# STM32U5xx register map
File version: 1.3
Registers are 32-bit, read-write, reset 0x0 unless marked. A register's access mark holds for its fields unless they carry their own. Offsets are from the block's base; [hi:lo] are bit positions; {n}, {i} and the like mark numbered series.

## RCC — Reset and clock control
Base 0x46020C00
Same registers: SEC_RCC 0x56020C00
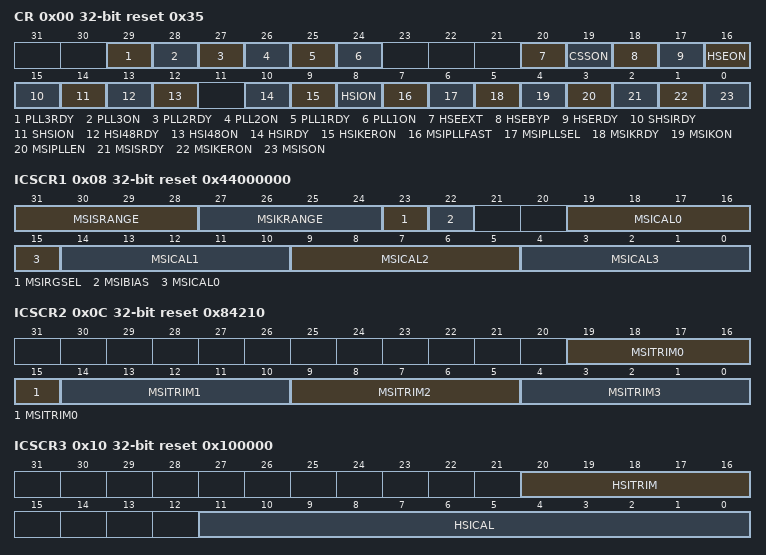
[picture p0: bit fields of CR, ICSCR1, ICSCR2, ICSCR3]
0x00 CR access per field reset 0x35 — Clock control register
  [29] PLL3RDY ro — PLL3 clock ready flag
  [28] PLL3ON rw — PLL3 enable
  [27] PLL2RDY ro — PLL2 clock ready flag
  [26] PLL2ON rw — PLL2 enable
  [25] PLL1RDY ro — PLL1 clock ready flag
  [24] PLL1ON rw — PLL1 enable
  [20] HSEEXT rw — SRAM3 page 5 (64 Kbytes) power-down in Stop modes
  [19] CSSON rw — Clock security system enable
  [18] HSEBYP rw — HSE crystal oscillator bypass
  [17] HSERDY ro — HSE clock ready flag
  [16] HSEON rw — HSE clock enable
  [15] SHSIRDY ro — SHSI clock ready flag
  [14] SHSION rw — SHSI clock enable
  [13] HSI48RDY ro — HSI48 clock ready flag
  [12] HSI48ON rw — HSI48 clock enable
  [10] HSIRDY ro — HSI16 clock ready flag
  [9] HSIKERON rw — HSI16 enable for some peripheral kernels
  [8] HSION rw — HSI16 clock enable
  [7] MSIPLLFAST rw — MSI PLL mode fast startup
  [6] MSIPLLSEL rw — MSI clock with PLL mode selection
  [5] MSIKRDY ro — MSIK clock ready flag
  [4] MSIKON rw — MSIK clock enable
  [3] MSIPLLEN rw — MSI clock PLL-mode enable
  [2] MSISRDY ro — MSIS clock ready flag
  [1] MSIKERON rw — MSI enable for some peripheral kernels
  [0] MSISON rw — MSIS clock enable
0x08 ICSCR1 access per field reset 0x44000000 — Internal clock sources calibration register 1
  [31:28] MSISRANGE rw — MSIS clock ranges
  [27:24] MSIKRANGE rw — MSIK clock ranges
  [23] MSIRGSEL rw — MSI clock range selection
  [22] MSIBIAS rw — MSI bias mode selection
  [19:15] MSICAL0 ro — MSI clock calibration
  [14:10] MSICAL1 ro — MSIRC1 clock calibration
  [9:5] MSICAL2 ro — MSIRC2 clock calibration
  [4:0] MSICAL3 ro — MSIRC3 clock calibration
0x0C ICSCR2 reset 0x84210 — Internal clock sources calibration register 2
  [19:15] MSITRIM0 — MSI clock calibration
  [14:10] MSITRIM1 — MSIRC1 clock calibration
  [9:5] MSITRIM2 — MSIRC2 clock calibration
  [4:0] MSITRIM3 — MSIRC3 clock calibration
0x10 ICSCR3 access per field reset 0x100000 — Internal clock sources calibration register 3
  [20:16] HSITRIM rw — HSI clock trimming
  [11:0] HSICAL ro — HSI clock calibration
0x14 CRRCR ro — clock recovery RC register
  [8:0] HSI48CAL — HSI48 clock calibration
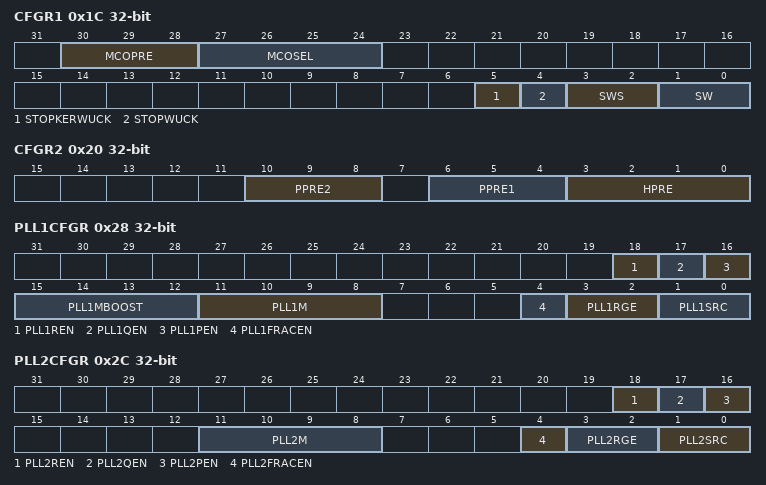
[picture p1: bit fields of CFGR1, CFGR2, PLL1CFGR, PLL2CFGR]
0x1C CFGR1 access per field — clock configuration register 1
  [30:28] MCOPRE rw — microcontroller clock output prescaler
  [27:24] MCOSEL rw — microcontroller clock output
  [5] STOPKERWUCK rw — wakeup from Stop kernel clock automatic enable selection
  [4] STOPWUCK rw — wakeup from Stop and CSS backup clock selection
  [3:2] SWS ro — system clock switch status
  [1:0] SW rw — system clock switch
0x20 CFGR2 — clock configuration register 2
  [10:8] PPRE2 — APB2 prescaler
  [6:4] PPRE1 — APB1 prescaler
  [3:0] HPRE — AHB prescaler
0x24 CFGR3 — clock configuration register 3
  [6:4] PPRE3 — APB3 prescaler
0x28 PLL1CFGR — PLL1 configuration register
  [18] PLL1REN — PLL1 DIVR divider output enable
  [17] PLL1QEN — PLL1 DIVQ divider output enable
  [16] PLL1PEN — PLL1 DIVP divider output enable
  [15:12] PLL1MBOOST — Prescaler for EPOD booster input clock
  [11:8] PLL1M — Prescaler for PLL1
  [4] PLL1FRACEN — PLL1 fractional latch enable
  [3:2] PLL1RGE — PLL1 input frequency range
  [1:0] PLL1SRC — PLL1 entry clock source
0x2C PLL2CFGR — PLL2 configuration register
  [18] PLL2REN — PLL2 DIVR divider output enable
  [17] PLL2QEN — PLL2 DIVQ divider output enable
  [16] PLL2PEN — PLL2 DIVP divider output enable
  [11:8] PLL2M — Prescaler for PLL2
  [4] PLL2FRACEN — PLL2 fractional latch enable
  [3:2] PLL2RGE — PLL2 input frequency range
  [1:0] PLL2SRC — PLL2 entry clock source
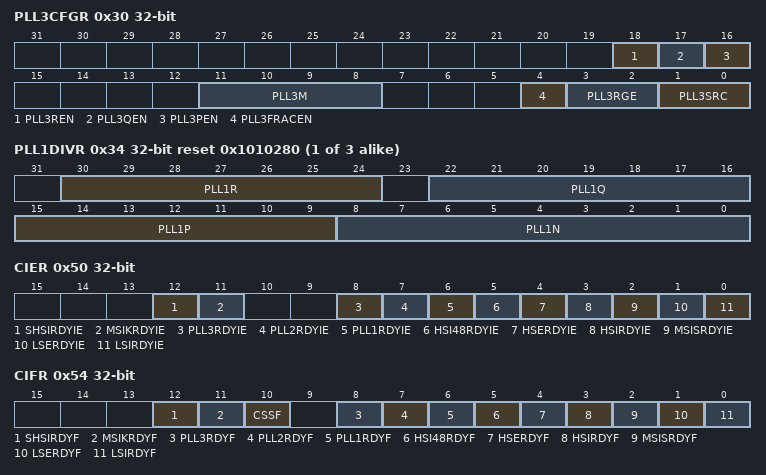
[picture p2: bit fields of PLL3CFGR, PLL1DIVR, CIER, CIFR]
0x30 PLL3CFGR — PLL3 configuration register
  [18] PLL3REN — PLL3 DIVR divider output enable
  [17] PLL3QEN — PLL3 DIVQ divider output enable
  [16] PLL3PEN — PLL3 DIVP divider output enable
  [11:8] PLL3M — Prescaler for PLL3
  [4] PLL3FRACEN — PLL3 fractional latch enable
  [3:2] PLL3RGE — PLL3 input frequency range
  [1:0] PLL3SRC — PLL3 entry clock source
{0x2C+8i} PLL{i}DIVR reset 0x1010280 (i=1..3) — PLL{i} dividers register
  [30:24] PLL{i}R — PLL{i} DIVR division factor
  [22:16] PLL{i}Q — PLL{i} DIVQ division factor
  [15:9] PLL{i}P — PLL{i} DIVP division factor
  [8:0] PLL{i}N — Multiplication factor for PLL{i} VCO
{0x30+8i} PLL{i}FRACR (i=1..3) — PLL{i} fractional divider register
  [15:3] PLL{i}FRACN — Fractional part of the multiplication factor for PLL{i} VCO
0x50 CIER — clock interrupt enable register
  [12] SHSIRDYIE — SHSI ready interrupt enable
  [11] MSIKRDYIE — MSIK ready interrupt enable
  [8] PLL3RDYIE — PLL3 ready interrupt enable
  [7] PLL2RDYIE — PLL2 ready interrupt enable
  [6] PLL1RDYIE — PLL ready interrupt enable
  [5] HSI48RDYIE — HSI48 ready interrupt enable
  [4] HSERDYIE — HSE ready interrupt enable
  [3] HSIRDYIE — HSI16 ready interrupt enable
  [2] MSISRDYIE — MSIS ready interrupt enable
  [1] LSERDYIE — LSE ready interrupt enable
  [0] LSIRDYIE — LSI ready interrupt enable
0x54 CIFR ro — clock interrupt flag register
  [12] SHSIRDYF — SHSI ready interrupt flag
  [11] MSIKRDYF — MSIK ready interrupt flag
  [10] CSSF — Clock security system interrupt flag
  [8] PLL3RDYF — PLL3 ready interrupt flag
  [7] PLL2RDYF — PLL2 ready interrupt flag
  [6] PLL1RDYF — PLL1 ready interrupt flag
  [5] HSI48RDYF — HSI48 ready interrupt flag
  [4] HSERDYF — HSE ready interrupt flag
  [3] HSIRDYF — HSI16 ready interrupt flag
  [2] MSISRDYF — MSIS ready interrupt flag
  [1] LSERDYF — LSE ready interrupt flag
  [0] LSIRDYF — LSI ready interrupt flag
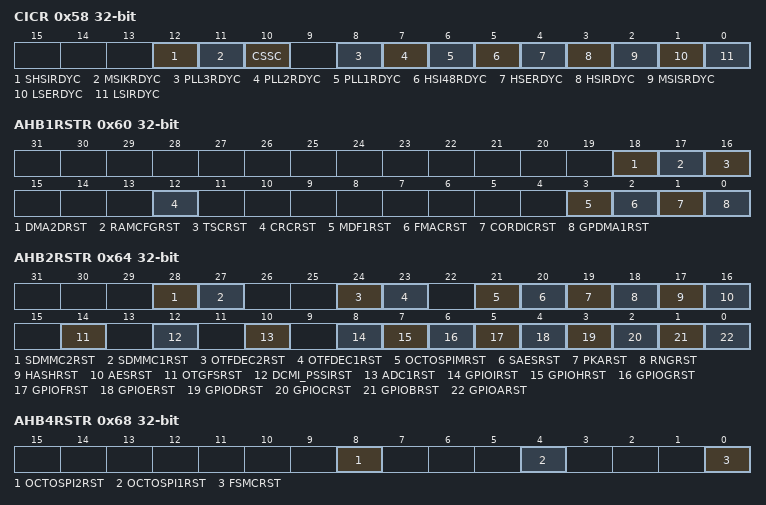
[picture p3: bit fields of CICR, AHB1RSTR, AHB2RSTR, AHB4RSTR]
0x58 CICR wo — clock interrupt clear register
  [12] SHSIRDYC — SHSI ready interrupt clear
  [11] MSIKRDYC — MSIK ready interrupt clear
  [10] CSSC — Clock security system interrupt clear
  [8] PLL3RDYC — PLL3 ready interrupt clear
  [7] PLL2RDYC — PLL2 ready interrupt clear
  [6] PLL1RDYC — PLL1 ready interrupt clear
  [5] HSI48RDYC — HSI48 ready interrupt clear
  [4] HSERDYC — HSE ready interrupt clear
  [3] HSIRDYC — HSI16 ready interrupt clear
  [2] MSISRDYC — MSIS ready interrupt clear
  [1] LSERDYC — LSE ready interrupt clear
  [0] LSIRDYC — LSI ready interrupt clear
0x60 AHB1RSTR — AHB1 peripheral reset register
  [18] DMA2DRST — DMA2D reset
  [17] RAMCFGRST — RAMCFG reset
  [16] TSCRST — TSC reset
  [12] CRCRST — CRC reset
  [3] MDF1RST — MDF1 reset
  [2] FMACRST — FMAC reset
  [1] CORDICRST — CORDIC reset
  [0] GPDMA1RST — GPDMA1 reset
0x64 AHB2RSTR — AHB2 peripheral reset register
  [28] SDMMC2RST — SDMMC2 reset
  [27] SDMMC1RST — SDMMC1 reset
  [24] OTFDEC2RST — OTFDEC2 reset
  [23] OTFDEC1RST — OTFDEC1 reset
  [21] OCTOSPIMRST — OCTOSPIM reset
  [20] SAESRST — SAES hardware accelerator reset
  [19] PKARST — PKA reset
  [18] RNGRST — Random number generator reset
  [17] HASHRST — Hash reset
  [16] AESRST — AES hardware accelerator reset
  [14] OTGFSRST — OTGFS reset
  [12] DCMI_PSSIRST — DCMI and PSSI reset
  [10] ADC1RST — ADC1 reset
  [8] GPIOIRST — O port I reset
  [7] GPIOHRST — O port H reset
  [6] GPIOGRST — O port G reset
  [5] GPIOFRST — O port F reset
  [4] GPIOERST — O port E reset
  [3] GPIODRST — O port D reset
  [2] GPIOCRST — O port C reset
  [1] GPIOBRST — O port B reset
  [0] GPIOARST — O port A reset
0x68 AHB4RSTR — AHB4 peripheral reset register
  [8] OCTOSPI2RST — OCTOSPI2 reset
  [4] OCTOSPI1RST — OCTOSPI1 reset
  [0] FSMCRST — Flexible memory controller reset
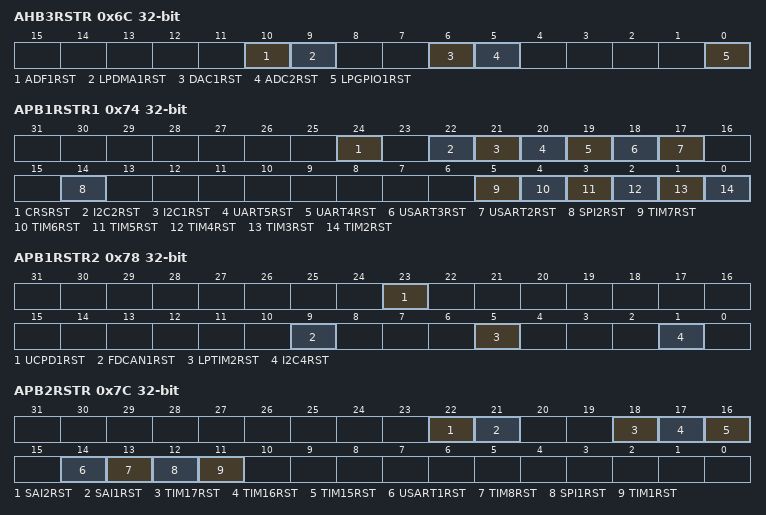
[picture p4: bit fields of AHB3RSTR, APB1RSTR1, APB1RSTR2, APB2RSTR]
0x6C AHB3RSTR — AHB3 peripheral reset register
  [10] ADF1RST — ADF1 reset
  [9] LPDMA1RST — LPDMA1 reset
  [6] DAC1RST — DAC1 reset
  [5] ADC2RST — ADC2 reset
  [0] LPGPIO1RST — LPGPIO1 reset
0x74 APB1RSTR1 — APB1 peripheral reset register 1
  [24] CRSRST — CRS reset
  [22] I2C2RST — I2C2 reset
  [21] I2C1RST — I2C1 reset
  [20] UART5RST — UART5 reset
  [19] UART4RST — UART4 reset
  [18] USART3RST — USART3 reset
  [17] USART2RST — USART2 reset
  [14] SPI2RST — SPI2 reset
  [5] TIM7RST — TIM7 reset
  [4] TIM6RST — TIM6 reset
  [3] TIM5RST — TIM5 reset
  [2] TIM4RST — TIM3 reset
  [1] TIM3RST — TIM3 reset
  [0] TIM2RST — TIM2 reset
0x78 APB1RSTR2 — APB1 peripheral reset register 2
  [23] UCPD1RST — UCPD1 reset
  [9] FDCAN1RST — FDCAN1 reset
  [5] LPTIM2RST — LPTIM2 reset
  [1] I2C4RST — I2C4 Reset
0x7C APB2RSTR — APB2 peripheral reset register
  [22] SAI2RST — SAI2 reset
  [21] SAI1RST — SAI1 reset
  [18] TIM17RST — TIM17 reset
  [17] TIM16RST — TIM16 reset
  [16] TIM15RST — TIM15 reset
  [14] USART1RST — USART1 reset
  [13] TIM8RST — TIM8 reset
  [12] SPI1RST — SPI1 reset
  [11] TIM1RST — TIM1 reset
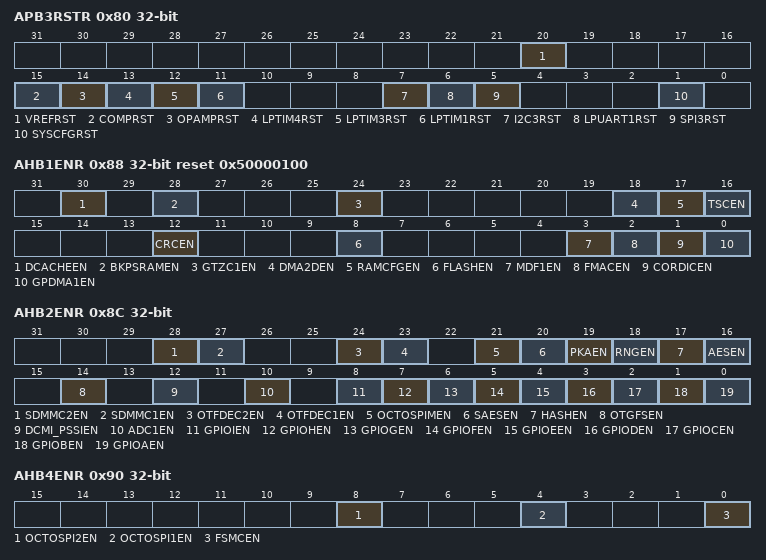
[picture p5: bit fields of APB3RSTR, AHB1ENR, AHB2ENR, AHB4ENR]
0x80 APB3RSTR — APB3 peripheral reset register
  [20] VREFRST — VREFBUF reset
  [15] COMPRST — COMP reset
  [14] OPAMPRST — OPAMP reset
  [13] LPTIM4RST — LPTIM4 reset
  [12] LPTIM3RST — LPTIM3 reset
  [11] LPTIM1RST — LPTIM1 reset
  [7] I2C3RST — I2C3 reset
  [6] LPUART1RST — LPUART1 reset
  [5] SPI3RST — SPI3 reset
  [1] SYSCFGRST — SYSCFG reset
0x88 AHB1ENR reset 0x50000100 — AHB1 peripheral clock enable register
  [30] DCACHEEN — DCACHE clock enable
  [28] BKPSRAMEN — BKPSRAM clock enable
  [24] GTZC1EN — GTZC1 clock enable
  [18] DMA2DEN — DMA2D clock enable
  [17] RAMCFGEN — RAMCFG clock enable
  [16] TSCEN — Touch sensing controller clock enable
  [12] CRCEN — CRC clock enable
  [8] FLASHEN — FLASH clock enable
  [3] MDF1EN — MDF1 clock enable
  [2] FMACEN — FMAC clock enable
  [1] CORDICEN — CORDIC clock enable
  [0] GPDMA1EN — GPDMA1 clock enable
0x8C AHB2ENR — AHB2 peripheral clock enable register
  [28] SDMMC2EN — SDMMC2 clock enable
  [27] SDMMC1EN — SDMMC1 clock enable
  [24] OTFDEC2EN — OTFDEC2 clock enable
  [23] OTFDEC1EN — OTFDEC1 clock enable
  [21] OCTOSPIMEN — OCTOSPIM clock enable
  [20] SAESEN — SAES clock enable
  [19] PKAEN — PKA clock enable
  [18] RNGEN — RNG clock enable
  [17] HASHEN — HASH clock enable
  [16] AESEN — AES clock enable
  [14] OTGFSEN — OTGFS clock enable
  [12] DCMI_PSSIEN — DCMI and PSSI clock enable
  [10] ADC1EN — ADC1 clock enable
  [8] GPIOIEN — IO port I clock enable
  [7] GPIOHEN — IO port H clock enable
  [6] GPIOGEN — IO port G clock enable
  [5] GPIOFEN — IO port F clock enable
  [4] GPIOEEN — IO port E clock enable
  [3] GPIODEN — IO port D clock enable
  [2] GPIOCEN — IO port C clock enable
  [1] GPIOBEN — IO port B clock enable
  [0] GPIOAEN — IO port A clock enable
0x90 AHB4ENR — AHB4 peripheral clock enable register
  [8] OCTOSPI2EN — OCTOSPI2 clock enable
  [4] OCTOSPI1EN — OCTOSPI1 clock enable
  [0] FSMCEN — FSMC clock enable
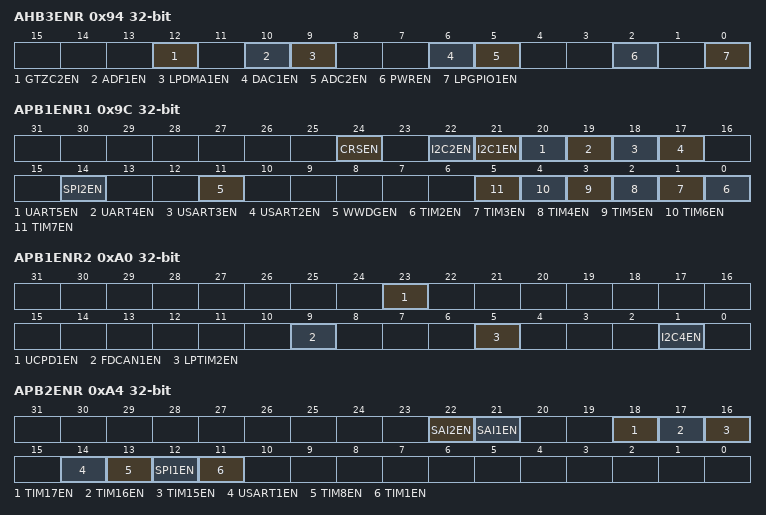
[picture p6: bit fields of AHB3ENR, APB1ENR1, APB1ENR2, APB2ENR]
0x94 AHB3ENR — AHB3 peripheral clock enable register
  [12] GTZC2EN — GTZC2 clock enable
  [10] ADF1EN — ADF1 clock enable
  [9] LPDMA1EN — LPDMA1 clock enable
  [6] DAC1EN — DAC1 clock enable
  [5] ADC2EN — ADC2 clock enable
  [2] PWREN — PWR clock enable
  [0] LPGPIO1EN — LPGPIO1 enable
0x9C APB1ENR1 — APB1 peripheral clock enable register 1
  [24] CRSEN — CRS clock enable
  [22] I2C2EN — I2C2 clock enable
  [21] I2C1EN — I2C1 clock enable
  [20] UART5EN — UART5 clock enable
  [19] UART4EN — UART4 clock enable
  [18] USART3EN — USART3 clock enable
  [17] USART2EN — USART2 clock enable
  [14] SPI2EN — SPI2 clock enable
  [11] WWDGEN — WWDG clock enable
  [n-2] TIM{n}EN (n=2..7) — TIM{n} clock enable
0xA0 APB1ENR2 — APB1 peripheral clock enable register 2
  [23] UCPD1EN — UCPD1 clock enable
  [9] FDCAN1EN — FDCAN1 clock enable
  [5] LPTIM2EN — LPTIM2 clock enable
  [1] I2C4EN — I2C4 clock enable
0xA4 APB2ENR — APB2 peripheral clock enable register
  [22] SAI2EN — SAI2 clock enable
  [21] SAI1EN — SAI1 clock enable
  [18] TIM17EN — TIM17 clock enable
  [17] TIM16EN — TIM16 clock enable
  [16] TIM15EN — TIM15 clock enable
  [14] USART1EN — USART1clock enable
  [13] TIM8EN — TIM8 clock enable
  [12] SPI1EN — SPI1 clock enable
  [11] TIM1EN — TIM1 clock enable
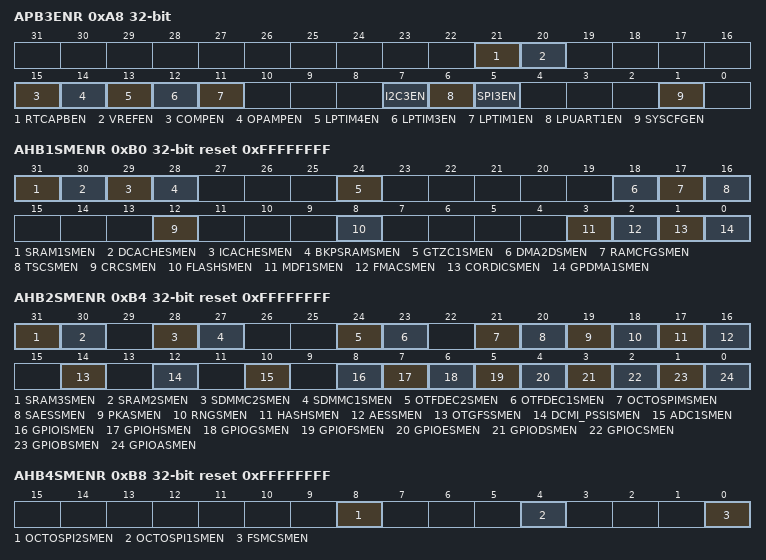
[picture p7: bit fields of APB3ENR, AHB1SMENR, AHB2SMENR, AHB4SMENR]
0xA8 APB3ENR — APB3 peripheral clock enable register
  [21] RTCAPBEN, [20] VREFEN, [15] COMPEN, [14] OPAMPEN, [13] LPTIM4EN, [12] LPTIM3EN, [11] LPTIM1EN, [7] I2C3EN, [6] LPUART1EN, [5] SPI3EN, [1] SYSCFGEN
0xB0 AHB1SMENR reset 0xFFFFFFFF — AHB1 peripheral clocks enable in Sleep and Stop modes register
  [31] SRAM1SMEN
  [30] DCACHESMEN
  [29] ICACHESMEN — CACHESMEN
  [28] BKPSRAMSMEN
  [24] GTZC1SMEN
  [18] DMA2DSMEN
  [17] RAMCFGSMEN
  [16] TSCSMEN
  [12] CRCSMEN
  [8] FLASHSMEN
  [3] MDF1SMEN
  [2] FMACSMEN
  [1] CORDICSMEN
  [0] GPDMA1SMEN
0xB4 AHB2SMENR reset 0xFFFFFFFF — AHB2 peripheral clocks enable in Sleep and Stop modes register
  [31] SRAM3SMEN, [30] SRAM2SMEN, [28] SDMMC2SMEN, [27] SDMMC1SMEN, [24] OTFDEC2SMEN, [23] OTFDEC1SMEN, [21] OCTOSPIMSMEN, [20] SAESSMEN, [19] PKASMEN, [18] RNGSMEN, [17] HASHSMEN, [16] AESSMEN, [14] OTGFSSMEN, [12] DCMI_PSSISMEN, [10] ADC1SMEN, [8] GPIOISMEN, [7] GPIOHSMEN, [6] GPIOGSMEN, [5] GPIOFSMEN, [4] GPIOESMEN, [3] GPIODSMEN, [2] GPIOCSMEN, [1] GPIOBSMEN, [0] GPIOASMEN
0xB8 AHB4SMENR reset 0xFFFFFFFF — AHB4 peripheral clocks enable in Sleep and Stop modes register
  [8] OCTOSPI2SMEN, [4] OCTOSPI1SMEN, [0] FSMCSMEN
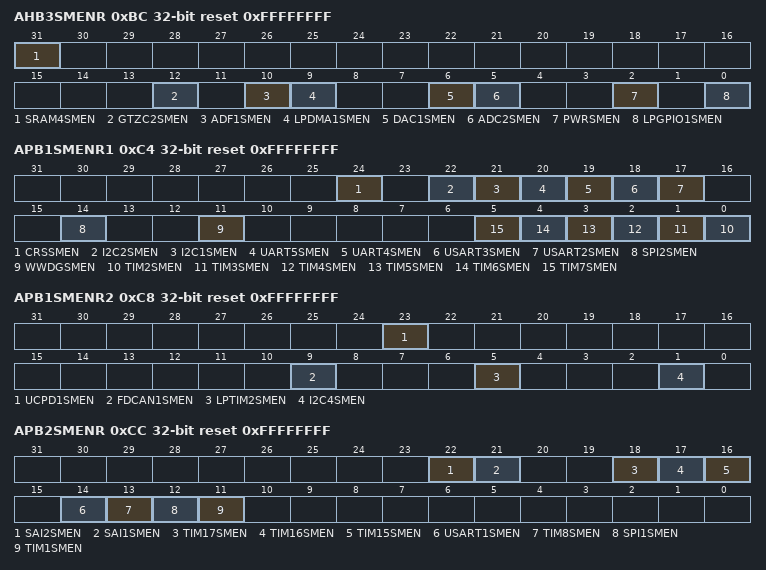
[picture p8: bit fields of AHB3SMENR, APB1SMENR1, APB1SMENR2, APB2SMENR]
0xBC AHB3SMENR reset 0xFFFFFFFF — AHB3 peripheral clocks enable in Sleep and Stop modes register
  [31] SRAM4SMEN, [12] GTZC2SMEN, [10] ADF1SMEN, [9] LPDMA1SMEN, [6] DAC1SMEN, [5] ADC2SMEN, [2] PWRSMEN, [0] LPGPIO1SMEN
0xC4 APB1SMENR1 reset 0xFFFFFFFF — APB1 peripheral clocks enable in Sleep and Stop modes register 1
  [24] CRSSMEN, [22] I2C2SMEN, [21] I2C1SMEN, [20] UART5SMEN, [19] UART4SMEN, [18] USART3SMEN, [17] USART2SMEN, [14] SPI2SMEN, [11] WWDGSMEN, [n-2] TIM{n}SMEN (n=2..7)
0xC8 APB1SMENR2 reset 0xFFFFFFFF — APB1 peripheral clocks enable in Sleep and Stop modes register 2
  [23] UCPD1SMEN, [9] FDCAN1SMEN, [5] LPTIM2SMEN, [1] I2C4SMEN
0xCC APB2SMENR reset 0xFFFFFFFF — APB2 peripheral clocks enable in Sleep and Stop modes register
  [22] SAI2SMEN, [21] SAI1SMEN, [18] TIM17SMEN, [17] TIM16SMEN, [16] TIM15SMEN, [14] USART1SMEN, [13] TIM8SMEN, [12] SPI1SMEN, [11] TIM1SMEN
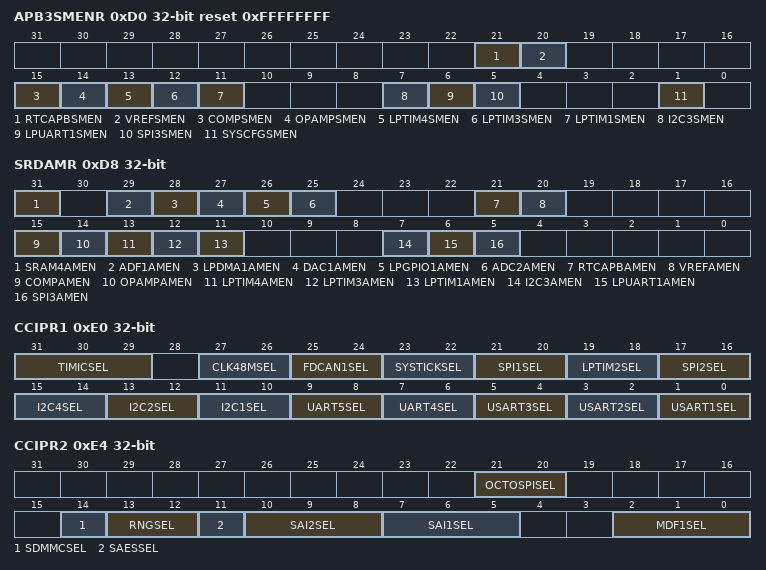
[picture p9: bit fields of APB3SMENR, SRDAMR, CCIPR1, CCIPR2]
0xD0 APB3SMENR reset 0xFFFFFFFF — APB3 peripheral clocks enable in Sleep and Stop modes register
  [21] RTCAPBSMEN, [20] VREFSMEN, [15] COMPSMEN, [14] OPAMPSMEN, [13] LPTIM4SMEN, [12] LPTIM3SMEN, [11] LPTIM1SMEN, [7] I2C3SMEN, [6] LPUART1SMEN, [5] SPI3SMEN, [1] SYSCFGSMEN
0xD8 SRDAMR — Smart run domain peripheral autonomous mode register
  [31] SRAM4AMEN, [29] ADF1AMEN, [28] LPDMA1AMEN, [27] DAC1AMEN, [26] LPGPIO1AMEN, [25] ADC2AMEN, [21] RTCAPBAMEN, [20] VREFAMEN, [15] COMPAMEN, [14] OPAMPAMEN, [13] LPTIM4AMEN, [12] LPTIM3AMEN, [11] LPTIM1AMEN, [7] I2C3AMEN, [6] LPUART1AMEN, [5] SPI3AMEN
0xE0 CCIPR1 — peripherals independent clock configuration register 1
  [31:29] TIMICSEL, [27:26] CLK48MSEL, [25:24] FDCAN1SEL, [23:22] SYSTICKSEL, [21:20] SPI1SEL, [19:18] LPTIM2SEL, [17:16] SPI2SEL, [15:14] I2C4SEL, [13:12] I2C2SEL, [11:10] I2C1SEL, [9:8] UART5SEL, [7:6] UART4SEL, [5:4] USART3SEL, [3:2] USART2SEL, [1:0] USART1SEL
0xE4 CCIPR2 — peripherals independent clock configuration register 2
  [21:20] OCTOSPISEL, [14] SDMMCSEL, [13:12] RNGSEL, [11] SAESSEL, [10:8] SAI2SEL, [7:5] SAI1SEL, [2:0] MDF1SEL
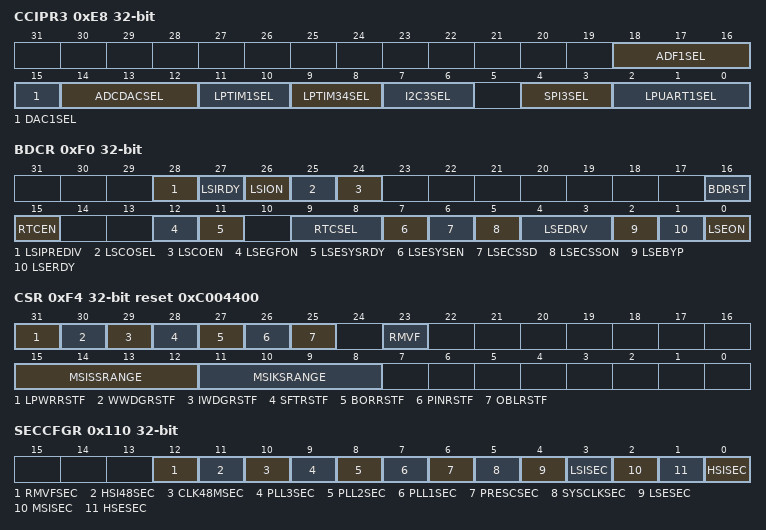
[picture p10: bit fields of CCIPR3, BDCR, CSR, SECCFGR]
0xE8 CCIPR3 — peripherals independent clock configuration register 3
  [18:16] ADF1SEL, [15] DAC1SEL, [14:12] ADCDACSEL, [11:10] LPTIM1SEL, [9:8] LPTIM34SEL, [7:6] I2C3SEL, [4:3] SPI3SEL, [2:0] LPUART1SEL
0xF0 BDCR access per field — Backup domain control register
  [28] LSIPREDIV rw, [27] LSIRDY rw, [26] LSION rw, [25] LSCOSEL rw, [24] LSCOEN rw, [16] BDRST rw, [15] RTCEN rw, [12] LSEGFON rw, [11] LSESYSRDY ro, [9:8] RTCSEL rw, [7] LSESYSEN rw, [6] LSECSSD ro, [5] LSECSSON rw, [4:3] LSEDRV rw, [2] LSEBYP rw, [1] LSERDY ro, [0] LSEON rw
0xF4 CSR access per field reset 0xC004400 — control/status register
  [31] LPWRRSTF ro, [30] WWDGRSTF ro, [29] IWDGRSTF ro, [28] SFTRSTF ro, [27] BORRSTF ro, [26] PINRSTF ro, [25] OBLRSTF ro, [23] RMVF rw, [15:12] MSISSRANGE rw, [11:8] MSIKSRANGE rw
0x110 SECCFGR — secure configuration register
  [12] RMVFSEC, [11] HSI48SEC, [10] CLK48MSEC, [9] PLL3SEC, [8] PLL2SEC, [7] PLL1SEC, [6] PRESCSEC, [5] SYSCLKSEC, [4] LSESEC, [3] LSISEC, [2] MSISEC, [1] HSESEC, [0] HSISEC
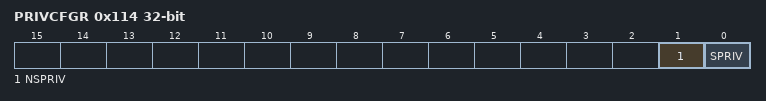
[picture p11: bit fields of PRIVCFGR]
0x114 PRIVCFGR — privilege configuration register
  [1] NSPRIV, [0] SPRIV
